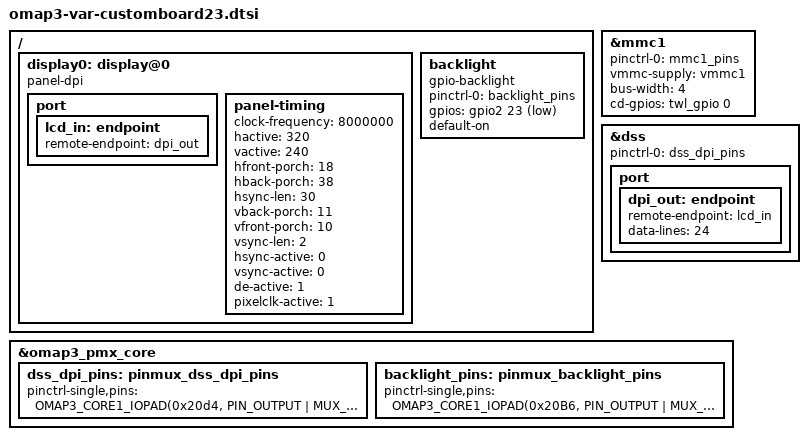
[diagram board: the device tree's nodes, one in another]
/*
 * Copyright (C) 2012 Florian Vaussard, EPFL Mobots group
 *
 * This program is free software; you can redistribute it and/or modify
 * it under the terms of the GNU General Public License version 2 as
 * published by the Free Software Foundation.
 */
 
#include "omap3-var-som-om3x.dtsi"
 
/ {
	display0: display@0 {
		compatible = "panel-dpi";
		port {
			lcd_in: endpoint {
				remote-endpoint = <&dpi_out>;
			};
		};

		panel-timing {
			clock-frequency = <8000000>;
			hactive = <320>;
			vactive = <240>;
			hfront-porch = <18>;
			hback-porch = <38>;
			hsync-len = <30>;
			vback-porch = <11>;
			vfront-porch = <10>;
			vsync-len = <2>;
			hsync-active = <0>;
			vsync-active = <0>;
			de-active = <1>;
			pixelclk-active = <1>;
		};
	};
	
        backlight {
		pinctrl-names = "default";
		pinctrl-0 = <&backlight_pins>;
                compatible = "gpio-backlight";
                gpios = <&gpio2 23 GPIO_ACTIVE_LOW>;
                default-on;
		status = "okay";
        };
};

&mmc1 {
	pinctrl-names = "default";
	pinctrl-0 = <&mmc1_pins>;
	vmmc-supply = <&vmmc1>;
	bus-width = <4>;
	cd-gpios = <&twl_gpio 0 0>;
};

&dss {
	status = "ok";

	pinctrl-names = "default";
	pinctrl-0 = <&dss_dpi_pins>;

	port {
		dpi_out: endpoint {
			remote-endpoint = <&lcd_in>;
			data-lines = <24>;
		};
	};
};


&omap3_pmx_core {	
	dss_dpi_pins: pinmux_dss_dpi_pins {
		pinctrl-single,pins = <
			OMAP3_CORE1_IOPAD(0x20d4, PIN_OUTPUT | MUX_MODE0)	/* dss_pclk.dss_pclk */
			OMAP3_CORE1_IOPAD(0x20d6, PIN_OUTPUT | MUX_MODE0)	/* dss_hsync.dss_hsync */
			OMAP3_CORE1_IOPAD(0x20d8, PIN_OUTPUT | MUX_MODE0)	/* dss_vsync.dss_vsync */
			OMAP3_CORE1_IOPAD(0x20da, PIN_OUTPUT | MUX_MODE0)	/* dss_acbias.dss_acbias */
			OMAP3_CORE1_IOPAD(0x20dc, PIN_OUTPUT | MUX_MODE0)	/* dss_data0.dss_data0 */
			OMAP3_CORE1_IOPAD(0x20de, PIN_OUTPUT | MUX_MODE0)	/* dss_data1.dss_data1 */
			OMAP3_CORE1_IOPAD(0x20e0, PIN_OUTPUT | MUX_MODE0)	/* dss_data2.dss_data2 */
			OMAP3_CORE1_IOPAD(0x20e2, PIN_OUTPUT | MUX_MODE0)	/* dss_data3.dss_data3 */
			OMAP3_CORE1_IOPAD(0x20e4, PIN_OUTPUT | MUX_MODE0)	/* dss_data4.dss_data4 */
			OMAP3_CORE1_IOPAD(0x20e6, PIN_OUTPUT | MUX_MODE0)	/* dss_data5.dss_data5 */
			OMAP3_CORE1_IOPAD(0x20e8, PIN_OUTPUT | MUX_MODE0)	/* dss_data6.dss_data6 */
			OMAP3_CORE1_IOPAD(0x20ea, PIN_OUTPUT | MUX_MODE0)	/* dss_data7.dss_data7 */
			OMAP3_CORE1_IOPAD(0x20ec, PIN_OUTPUT | MUX_MODE0)	/* dss_data8.dss_data8 */
			OMAP3_CORE1_IOPAD(0x20ee, PIN_OUTPUT | MUX_MODE0)	/* dss_data9.dss_data9 */
			OMAP3_CORE1_IOPAD(0x20f0, PIN_OUTPUT | MUX_MODE0)	/* dss_data10.dss_data10 */
			OMAP3_CORE1_IOPAD(0x20f2, PIN_OUTPUT | MUX_MODE0)	/* dss_data11.dss_data11 */
			OMAP3_CORE1_IOPAD(0x20f4, PIN_OUTPUT | MUX_MODE0)	/* dss_data12.dss_data12 */
			OMAP3_CORE1_IOPAD(0x20f6, PIN_OUTPUT | MUX_MODE0)	/* dss_data13.dss_data13 */
			OMAP3_CORE1_IOPAD(0x20f8, PIN_OUTPUT | MUX_MODE0)	/* dss_data14.dss_data14 */
			OMAP3_CORE1_IOPAD(0x20fa, PIN_OUTPUT | MUX_MODE0)	/* dss_data15.dss_data15 */
			OMAP3_CORE1_IOPAD(0x20fc, PIN_OUTPUT | MUX_MODE0)	/* dss_data16.dss_data16 */
			OMAP3_CORE1_IOPAD(0x20fe, PIN_OUTPUT | MUX_MODE0)	/* dss_data17.dss_data17 */
			OMAP3_CORE1_IOPAD(0x2100, PIN_OUTPUT | MUX_MODE0)	/* dss_data18.dss_data18 */
			OMAP3_CORE1_IOPAD(0x2102, PIN_OUTPUT | MUX_MODE0)	/* dss_data19.dss_data19 */
			OMAP3_CORE1_IOPAD(0x2104, PIN_OUTPUT | MUX_MODE0)	/* dss_data20.dss_data20 */
			OMAP3_CORE1_IOPAD(0x2106, PIN_OUTPUT | MUX_MODE0)	/* dss_data21.dss_data21 */
			OMAP3_CORE1_IOPAD(0x2108, PIN_OUTPUT | MUX_MODE0)	/* dss_data22.dss_data22 */
			OMAP3_CORE1_IOPAD(0x210a, PIN_OUTPUT | MUX_MODE0)	/* dss_data23.dss_data23 */
		>;
	};
		
	backlight_pins: pinmux_backlight_pins {
		pinctrl-single,pins = <
			OMAP3_CORE1_IOPAD(0x20B6, PIN_OUTPUT | MUX_MODE4)	/* gpmc_ncs4.gpio_55 */
		>;
	};
};
 
